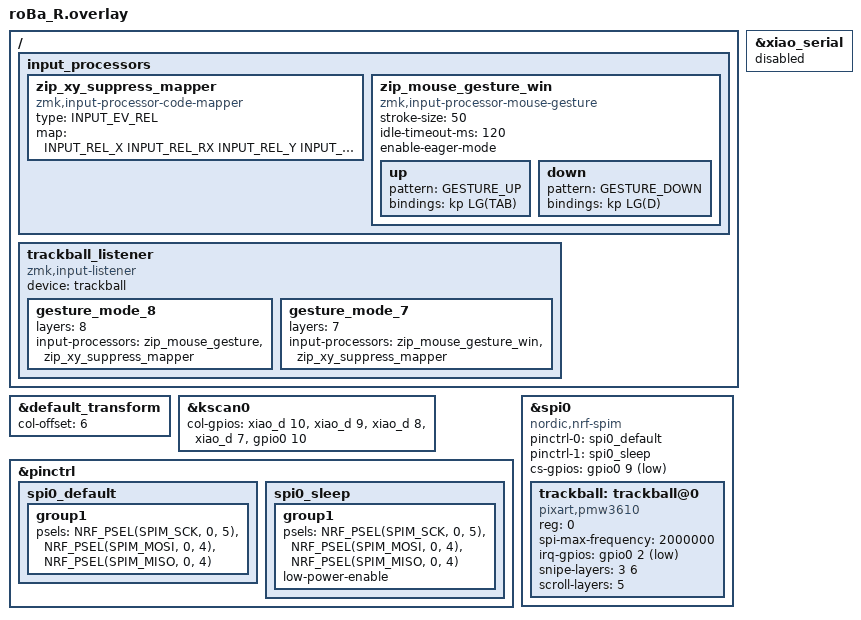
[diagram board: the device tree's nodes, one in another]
#include "roBa.dtsi"
#include <zephyr/dt-bindings/input/input-event-codes.h>
#include <mouse-gesture.dtsi>
#include <dt-bindings/zmk/keys.h>
#include <dt-bindings/zmk/modifiers.h>

&default_transform {
    col-offset = <6>;
};

/ {
  input_processors {
    zip_xy_suppress_mapper: zip_xy_suppress_mapper {
      compatible = "zmk,input-processor-code-mapper";
      #input-processor-cells = <0>;
      type = <INPUT_EV_REL>;
      map = <
        INPUT_REL_X INPUT_REL_RX
        INPUT_REL_Y INPUT_REL_RY
      >;
    };
    /* ★ 追加：Layer 7用ジェスチャープロセッサ（新しいノードラベル） */
    zip_mouse_gesture_win: zip_mouse_gesture_win {
      compatible = "zmk,input-processor-mouse-gesture";
      #input-processor-cells = <0>;

      stroke-size = <50>;
      idle-timeout-ms = <120>;
      enable-eager-mode;

      up {
        pattern = <GESTURE_UP>;
        bindings = <&kp LG(TAB)>;                 /* Win+Tab */
      };
      down {
        pattern = <GESTURE_DOWN>;
        bindings = <&kp LG(D)>;                   /* Win+D */
      };
    };
  };
};

&kscan0 {
        col-gpios
            = <&xiao_d 10 GPIO_ACTIVE_HIGH>
            , <&xiao_d 9 GPIO_ACTIVE_HIGH> 
            , <&xiao_d 8 GPIO_ACTIVE_HIGH> 
            , <&xiao_d 7 GPIO_ACTIVE_HIGH> 
            , <&gpio0 10 GPIO_ACTIVE_HIGH>
            ;
};

/ {
    trackball_listener {
        compatible = "zmk,input-listener";
        device = <&trackball>;

        gesture_mode_8 {
            layers = <8>;
            input-processors = <
                &zip_mouse_gesture
                &zip_xy_suppress_mapper
            >;
        };
        
        gesture_mode_7 {
            layers = <7>;
            input-processors = <
                &zip_mouse_gesture_win
                &zip_xy_suppress_mapper
            >;
        };
    };
};

&pinctrl {
    spi0_default: spi0_default {
        group1 {
            psels = <NRF_PSEL(SPIM_SCK, 0, 5)>,
                <NRF_PSEL(SPIM_MOSI, 0, 4)>,
                <NRF_PSEL(SPIM_MISO, 0, 4)>;
        };
    };

    spi0_sleep: spi0_sleep {
        group1 {
            psels = <NRF_PSEL(SPIM_SCK, 0, 5)>,
                <NRF_PSEL(SPIM_MOSI, 0, 4)>,
                <NRF_PSEL(SPIM_MISO, 0, 4)>;
            low-power-enable;
        };
    };
};

&xiao_serial { status = "disabled"; };

&spi0 {
    status = "okay";
    compatible = "nordic,nrf-spim";
    pinctrl-0 = <&spi0_default>;
    pinctrl-1 = <&spi0_sleep>;
    pinctrl-names = "default", "sleep";
    cs-gpios = <&gpio0 9 GPIO_ACTIVE_LOW>;

    trackball: trackball@0 {
        status = "okay";
        compatible = "pixart,pmw3610";
        reg = <0>;
        spi-max-frequency = <2000000>;
        irq-gpios = <&gpio0 2 (GPIO_ACTIVE_LOW | GPIO_PULL_UP)>;
        snipe-layers = <3 6>;
        //automouse-layer = <4>;
        scroll-layers = <5>;
    };
};


